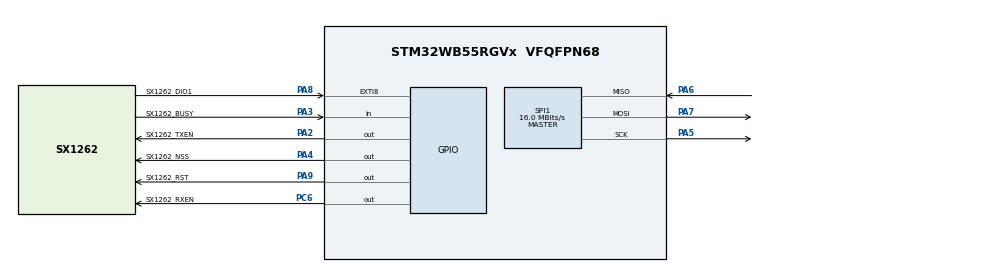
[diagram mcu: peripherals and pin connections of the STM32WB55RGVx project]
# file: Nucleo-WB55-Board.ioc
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Mcu.Family=STM32WB
Mcu.Name=STM32WB55RGVx
Mcu.Package=VFQFPN68
NVIC.EXTI0_IRQn=true\:0\:0\:false\:false\:true\:false\:true\:true
NVIC.EXTI1_IRQn=true\:0\:0\:false\:false\:true\:false\:true\:true
NVIC.EXTI4_IRQn=true\:0\:0\:false\:false\:true\:false\:true\:true
NVIC.PriorityGroup=NVIC_PRIORITYGROUP_4
OSC_IN.GPIO_Label=RCC_OSC_IN
OSC_IN.Mode=HSE-External-Oscillator
OSC_IN.Signal=RCC_OSC_IN
OSC_OUT.GPIO_Label=RCC_OSC_OUT
OSC_OUT.Mode=HSE-External-Oscillator
OSC_OUT.Signal=RCC_OSC_OUT
P-NUCLEO-WB55-NUCLEO.BUTTON=1
P-NUCLEO-WB55-NUCLEO.BUTTON2=1
P-NUCLEO-WB55-NUCLEO.BUTTON3=1
P-NUCLEO-WB55-NUCLEO.LD1=true
P-NUCLEO-WB55-NUCLEO.LD2=true
P-NUCLEO-WB55-NUCLEO.LD3=true
P-NUCLEO-WB55-NUCLEO.VCP=true
PA11.GPIO_Label=USB_DM
PA11.Signal=USB_DM
PA12.GPIO_Label=USB_DP
PA12.Signal=USB_DP
PA13.GPIO_Label=JTMS
PA13.Mode=Serial_Wire
PA13.Signal=SYS_JTMS-SWDIO
PA14.GPIO_Label=JTCK
PA14.Mode=Serial_Wire
PA14.Signal=SYS_JTCK-SWCLK
PA2.GPIO_Label=SX1262_TXEN
PA2.Signal=GPIO_Output
PA3.GPIO_Label=SX1262_BUSY
PA3.Signal=GPIO_Input
PA4.GPIO_Label=SX1262_NSS
PA4.PinState=GPIO_PIN_SET
PA4.Signal=GPIO_Output
PA5.Mode=Full_Duplex_Master
PA5.Signal=SPI1_SCK
PA6.Mode=Full_Duplex_Master
PA6.Signal=SPI1_MISO
PA7.Mode=Full_Duplex_Master
PA7.Signal=SPI1_MOSI
PA8.GPIO_Label=SX1262_DIO1
PA8.Signal=GPXTI8
PA9.GPIO_Label=SX1262_RST
PA9.PinState=GPIO_PIN_SET
PA9.Signal=GPIO_Output
PB3.GPIO_Label=JTDO
PB3.Signal=SYS_JTDO-SWO
PB6.Signal=USART1_TX
PB7.Signal=USART1_RX
PC13.GPIO_Label=SYS_WKUP2
PC13.Signal=SYS_WKUP2
PC14-OSC32_IN.GPIO_Label=RCC_OSC32_IN
PC14-OSC32_IN.Mode=LSE-External-Oscillator
PC14-OSC32_IN.Signal=RCC_OSC32_IN
PC15-OSC32_OUT.GPIO_Label=RCC_OSC32_OUT
PC15-OSC32_OUT.Mode=LSE-External-Oscillator
PC15-OSC32_OUT.Signal=RCC_OSC32_OUT
PC6.GPIO_Label=SX1262_RXEN
PC6.PinState=GPIO_PIN_SET
PC6.Signal=GPIO_Output
ProjectManager.HeapSize=0x200
ProjectManager.StackSize=0x400
ProjectManager.TargetToolchain=STM32CubeIDE
RCC.ADCFreq_Value=128000000
RCC.AHBFreq_Value=32000000
RCC.APB1Freq_Value=32000000
RCC.APB1TimFreq_Value=32000000
RCC.APB2Freq_Value=32000000
RCC.APB2TimFreq_Value=32000000
RCC.APB3Freq_Value=16000000
RCC.CortexFreq_Value=32000000
RCC.HCLKFreq_Value=32000000
RCC.HSE_VALUE=32000000
RCC.HSI48_VALUE=48000000
RCC.HSI_VALUE=16000000
RCC.MSIClockRange=RCC_MSIRANGE_10
RCC.SMPSCLockSelection=RCC_SMPSCLKSOURCE_HSI
RCC.SMPSCLockSelectionVirtual=RCC_SMPSCLKSOURCE_HSI
RCC.SMPSCLockSelectionVirtualVirtual=RCC_SMPSCLKSOURCE_HSI
RCC.SMPSDivider=1
RCC.SYSCLKFreq_VALUE=32000000
RCC.USBFreq_Value=128000000
RCC.VCOOutputFreq_Value=256000000
SPI1.CalculateBaudRate=16.0 MBits/s
SPI1.DataSize=SPI_DATASIZE_8BIT
SPI1.Direction=SPI_DIRECTION_2LINES
SPI1.Mode=SPI_MODE_MASTER
SPI1.VirtualType=VM_MASTER
VP_MEMORYMAP_VS_MEMORYMAP.Mode=CurAppReg
VP_P-NUCLEO-WB55-NUCLEO_VS_BSP_COMMON.Mode=COMMON
board=P-NUCLEO-WB55-NUCLEO

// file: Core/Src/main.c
/* USER CODE BEGIN Header */
/**
  ******************************************************************************
  * @file           : main.c
  * @brief          : Main program body
  ******************************************************************************
  * @attention
  *
  * Copyright (c) 2026 STMicroelectronics.
  * All rights reserved.
  *
  * This software is licensed under terms that can be found in the LICENSE file
  * in the root directory of this software component.
  * If no LICENSE file comes with this software, it is provided AS-IS.
  *
  ******************************************************************************
  */
/* USER CODE END Header */
#include "main.h"
#include "board_sx126x_calls.h"

COM_InitTypeDef BspCOMInit;
SPI_HandleTypeDef hspi1;

void SystemClock_Config(void);
void PeriphCommonClock_Config(void);
static void MX_GPIO_Init(void);
static void MX_SPI1_Init(void);

int main(void)
{

  /* MCU Configuration--------------------------------------------------------*/

  /* Reset of all peripherals, Initializes the Flash interface and the Systick. */
  HAL_Init();

  /* Configure the system clock */
  SystemClock_Config();

  /* Configure the peripherals common clocks */
  PeriphCommonClock_Config();

  /* Initialize all configured peripherals */
  MX_GPIO_Init();
  MX_SPI1_Init();

  /* USER CODE BEGIN 2 */
  setup_22dBm_Tx(NULL);		//as the name suggests
  rfswitch_Tx(NULL);		//configure the RF switch for TX
  HAL_Delay(100);
  sx126x_set_tx_cw(NULL);
  /* USER CODE END 2 */

  /* Initialize leds */
  BSP_LED_Init(LED_BLUE);
  BSP_LED_Init(LED_GREEN);
  BSP_LED_Init(LED_RED);

  /* Initialize USER push-button, will be used to trigger an interrupt each time it's pressed.*/
  BSP_PB_Init(BUTTON_SW1, BUTTON_MODE_EXTI);
  BSP_PB_Init(BUTTON_SW2, BUTTON_MODE_EXTI);
  BSP_PB_Init(BUTTON_SW3, BUTTON_MODE_EXTI);

  /* Initialize COM1 port (115200, 8 bits (7-bit data + 1 stop bit), no parity */
  BspCOMInit.BaudRate   = 115200;
  BspCOMInit.WordLength = COM_WORDLENGTH_8B;
  BspCOMInit.StopBits   = COM_STOPBITS_1;
  BspCOMInit.Parity     = COM_PARITY_NONE;
  BspCOMInit.HwFlowCtl  = COM_HWCONTROL_NONE;
  if (BSP_COM_Init(COM1, &BspCOMInit) != BSP_ERROR_NONE)
  {
    Error_Handler();
  }

  /* Infinite loop */
  while (1)
  {

	  //YIPPE I MADE IT BLINK!!!

  }
}

void SystemClock_Config(void)
{
  RCC_OscInitTypeDef RCC_OscInitStruct = {0};
  RCC_ClkInitTypeDef RCC_ClkInitStruct = {0};

  /** Configure the main internal regulator output voltage
  */
  __HAL_PWR_VOLTAGESCALING_CONFIG(PWR_REGULATOR_VOLTAGE_SCALE1);

  /** Initializes the RCC Oscillators according to the specified parameters
  * in the RCC_OscInitTypeDef structure.
  */
  RCC_OscInitStruct.OscillatorType = RCC_OSCILLATORTYPE_HSI|RCC_OSCILLATORTYPE_HSE
                              |RCC_OSCILLATORTYPE_MSI;
  RCC_OscInitStruct.HSEState = RCC_HSE_ON;
  RCC_OscInitStruct.HSIState = RCC_HSI_ON;
  RCC_OscInitStruct.MSIState = RCC_MSI_ON;
  RCC_OscInitStruct.HSICalibrationValue = RCC_HSICALIBRATION_DEFAULT;
  RCC_OscInitStruct.MSICalibrationValue = RCC_MSICALIBRATION_DEFAULT;
  RCC_OscInitStruct.MSIClockRange = RCC_MSIRANGE_10;
  RCC_OscInitStruct.PLL.PLLState = RCC_PLL_NONE;
  if (HAL_RCC_OscConfig(&RCC_OscInitStruct) != HAL_OK)
  {
    Error_Handler();
  }

  /** Configure the SYSCLKSource, HCLK, PCLK1 and PCLK2 clocks dividers
  */
  RCC_ClkInitStruct.ClockType = RCC_CLOCKTYPE_HCLK4|RCC_CLOCKTYPE_HCLK2
                              |RCC_CLOCKTYPE_HCLK|RCC_CLOCKTYPE_SYSCLK
                              |RCC_CLOCKTYPE_PCLK1|RCC_CLOCKTYPE_PCLK2;
  RCC_ClkInitStruct.SYSCLKSource = RCC_SYSCLKSOURCE_MSI;
  RCC_ClkInitStruct.AHBCLKDivider = RCC_SYSCLK_DIV1;
  RCC_ClkInitStruct.APB1CLKDivider = RCC_HCLK_DIV1;
  RCC_ClkInitStruct.APB2CLKDivider = RCC_HCLK_DIV1;
  RCC_ClkInitStruct.AHBCLK2Divider = RCC_SYSCLK_DIV1;
  RCC_ClkInitStruct.AHBCLK4Divider = RCC_SYSCLK_DIV1;

  if (HAL_RCC_ClockConfig(&RCC_ClkInitStruct, FLASH_LATENCY_1) != HAL_OK)
  {
    Error_Handler();
  }
}

void PeriphCommonClock_Config(void)
{
  RCC_PeriphCLKInitTypeDef PeriphClkInitStruct = {0};

  /** Initializes the peripherals clock
  */
  PeriphClkInitStruct.PeriphClockSelection = RCC_PERIPHCLK_SMPS;
  PeriphClkInitStruct.SmpsClockSelection = RCC_SMPSCLKSOURCE_HSI;
  PeriphClkInitStruct.SmpsDivSelection = RCC_SMPSCLKDIV_RANGE0;

  if (HAL_RCCEx_PeriphCLKConfig(&PeriphClkInitStruct) != HAL_OK)
  {
    Error_Handler();
  }
}

static void MX_SPI1_Init(void)
{

  /* SPI1 parameter configuration*/
  hspi1.Instance = SPI1;
  hspi1.Init.Mode = SPI_MODE_MASTER;
  hspi1.Init.Direction = SPI_DIRECTION_2LINES;
  hspi1.Init.DataSize = SPI_DATASIZE_8BIT;
  hspi1.Init.CLKPolarity = SPI_POLARITY_LOW;
  hspi1.Init.CLKPhase = SPI_PHASE_1EDGE;
  hspi1.Init.NSS = SPI_NSS_SOFT;
  hspi1.Init.BaudRatePrescaler = SPI_BAUDRATEPRESCALER_2;
  hspi1.Init.FirstBit = SPI_FIRSTBIT_MSB;
  hspi1.Init.TIMode = SPI_TIMODE_DISABLE;
  hspi1.Init.CRCCalculation = SPI_CRCCALCULATION_DISABLE;
  hspi1.Init.CRCPolynomial = 7;
  hspi1.Init.CRCLength = SPI_CRC_LENGTH_DATASIZE;
  hspi1.Init.NSSPMode = SPI_NSS_PULSE_ENABLE;
  if (HAL_SPI_Init(&hspi1) != HAL_OK)
  {
    Error_Handler();
  }

}

static void MX_GPIO_Init(void)
{
  GPIO_InitTypeDef GPIO_InitStruct = {0};

  /* GPIO Ports Clock Enable */
  __HAL_RCC_GPIOC_CLK_ENABLE();
  __HAL_RCC_GPIOA_CLK_ENABLE();
  __HAL_RCC_GPIOB_CLK_ENABLE();

  /*Configure GPIO pin Output Level */
  HAL_GPIO_WritePin(SX1262_TXEN_GPIO_Port, SX1262_TXEN_Pin, GPIO_PIN_RESET);

  /*Configure GPIO pin Output Level */
  HAL_GPIO_WritePin(GPIOA, SX1262_NSS_Pin|SX1262_RST_Pin, GPIO_PIN_SET);

  /*Configure GPIO pin Output Level */
  HAL_GPIO_WritePin(SX1262_RXEN_GPIO_Port, SX1262_RXEN_Pin, GPIO_PIN_SET);

  /*Configure GPIO pins : SX1262_TXEN_Pin SX1262_NSS_Pin SX1262_RST_Pin */
  GPIO_InitStruct.Pin = SX1262_TXEN_Pin|SX1262_NSS_Pin|SX1262_RST_Pin;
  GPIO_InitStruct.Mode = GPIO_MODE_OUTPUT_PP;
  GPIO_InitStruct.Pull = GPIO_NOPULL;
  GPIO_InitStruct.Speed = GPIO_SPEED_FREQ_LOW;
  HAL_GPIO_Init(GPIOA, &GPIO_InitStruct);

  /*Configure GPIO pin : SX1262_BUSY_Pin */
  GPIO_InitStruct.Pin = SX1262_BUSY_Pin;
  GPIO_InitStruct.Mode = GPIO_MODE_INPUT;
  GPIO_InitStruct.Pull = GPIO_NOPULL;
  HAL_GPIO_Init(SX1262_BUSY_GPIO_Port, &GPIO_InitStruct);

  /*Configure GPIO pin : SX1262_DIO1_Pin */
  GPIO_InitStruct.Pin = SX1262_DIO1_Pin;
  GPIO_InitStruct.Mode = GPIO_MODE_IT_RISING;
  GPIO_InitStruct.Pull = GPIO_NOPULL;
  HAL_GPIO_Init(SX1262_DIO1_GPIO_Port, &GPIO_InitStruct);

  /*Configure GPIO pin : SX1262_RXEN_Pin */
  GPIO_InitStruct.Pin = SX1262_RXEN_Pin;
  GPIO_InitStruct.Mode = GPIO_MODE_OUTPUT_PP;
  GPIO_InitStruct.Pull = GPIO_NOPULL;
  GPIO_InitStruct.Speed = GPIO_SPEED_FREQ_LOW;
  HAL_GPIO_Init(SX1262_RXEN_GPIO_Port, &GPIO_InitStruct);

  /*Configure GPIO pins : USB_DM_Pin USB_DP_Pin */
  GPIO_InitStruct.Pin = USB_DM_Pin|USB_DP_Pin;
  GPIO_InitStruct.Mode = GPIO_MODE_AF_PP;
  GPIO_InitStruct.Pull = GPIO_NOPULL;
  GPIO_InitStruct.Speed = GPIO_SPEED_FREQ_LOW;
  GPIO_InitStruct.Alternate = GPIO_AF10_USB;
  HAL_GPIO_Init(GPIOA, &GPIO_InitStruct);

}

void Error_Handler(void)
{
  __disable_irq();
  while (1)
  {
  }
}
